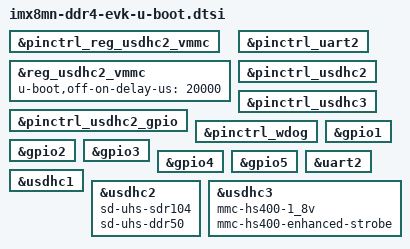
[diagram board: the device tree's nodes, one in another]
// SPDX-License-Identifier: GPL-2.0+
/*
 * Copyright 2019, 2021 NXP
 */

#include "imx8mn-u-boot.dtsi"

&pinctrl_reg_usdhc2_vmmc {
	bootph-pre-ram;
};

&reg_usdhc2_vmmc {
	u-boot,off-on-delay-us = <20000>;
};

&pinctrl_uart2 {
	bootph-pre-ram;
};

&pinctrl_usdhc2_gpio {
	bootph-pre-ram;
};

&pinctrl_usdhc2 {
	bootph-pre-ram;
};

&pinctrl_usdhc3 {
	bootph-pre-ram;
};

&pinctrl_wdog {
	bootph-pre-ram;
};

&gpio1 {
	bootph-pre-ram;
};

&gpio2 {
	bootph-pre-ram;
};

&gpio3 {
	bootph-pre-ram;
};

&gpio4 {
	bootph-pre-ram;
};

&gpio5 {
	bootph-pre-ram;
};

&uart2 {
	bootph-pre-ram;
};

&usdhc1 {
	bootph-pre-ram;
};

&usdhc2 {
	bootph-pre-ram;
	sd-uhs-sdr104;
	sd-uhs-ddr50;
};

&usdhc3 {
	bootph-pre-ram;
	mmc-hs400-1_8v;
	mmc-hs400-enhanced-strobe;
};
